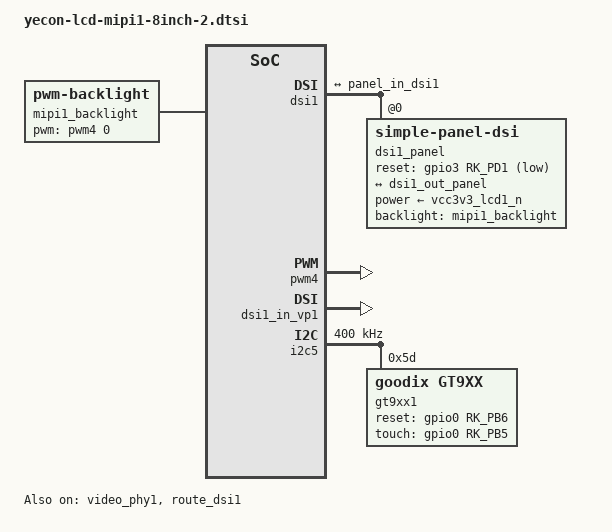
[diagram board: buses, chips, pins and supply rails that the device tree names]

/ {
	mipi1_backlight: mipi1-backlight {
		compatible = "pwm-backlight";
		pwms = <&pwm4 0 25000 0>;
		brightness-levels = <
            0   20  20  21  21  22  22  23
            23  24  24  25  25  26  26  27
            27  28  28  29  29  30  30  31
            31  32  32  33  33  34  34  35
            35  36  36  37  37  38  38  39
            40  41  42  43  44  45  46  47
            48  49  50  51  52  53  54  55
            56  57  58  59  60  61  62  63
            64  65  66  67  68  69  70  71
            72  73  74  75  76  77  78  79
            80  81  82  83  84  85  86  87
            88  89  90  91  92  93  94  95
            96  97  98  99  100 101 102 103
			104 105 106 107 108 109 110 111
			112 113 114 115 116 117 118 119
			120 121 122 123 124 125 126 127
			128 129 130 131 132 133 134 135
			136 137 138 139 140 141 142 143
			144 145 146 147 148 149 150 151
			152 153 154 155 156 157 158 159
			160 161 162 163 164 165 166 167
			168 169 170 171 172 173 174 175
			176 177 178 179 180 181 182 183
			184 185 186 187 188 189 190 191
			192 193 194 195 196 197 198 199
			200 201 202 203 204 205 206 207
			208 209 210 211 212 213 214 215
			216 217 218 219 220 221 222 223
			224 225 226 227 228 229 230 231
			232 233 234 235 236 237 238 239
			240 241 242 243 244 245 246 247
			248 249 250 251 252 253 254 255
		>;
		default-brightness-level = <200>;
	};
};

&vcc3v3_lcd1_n {
    status = "okay";
    gpio = <&gpio0 RK_PC7 GPIO_ACTIVE_HIGH>;
};

&dsi1 {
	status = "okay";
	rockchip,lane-rate = <480>;

	dsi1_panel: panel@0 {
		status = "okay";
		compatible = "simple-panel-dsi";
		reg = <0>;
		backlight = <&mipi1_backlight>;
		prepare-delay-ms = <10>;
		reset-delay-ms = <100>;
		init-delay-ms = <100>;
		enable-delay-ms = <10>;
		disable-delay-ms = <10>;
		unprepare-delay-ms = <10>;

		width-mm = <68>;
		height-mm = <121>;

		dsi,flags = <(MIPI_DSI_MODE_VIDEO | MIPI_DSI_MODE_VIDEO_BURST |
			      MIPI_DSI_MODE_LPM | MIPI_DSI_MODE_EOT_PACKET)>;
		dsi,format = <MIPI_DSI_FMT_RGB888>;
		dsi,lanes = <4>;

		panel-init-sequence = [
			39 00 04 FF 98 81 03
			15 00 02 01 00
			15 00 02 02 00
			15 00 02 03 73
			15 00 02 04 D7
			15 00 02 05 00
			15 00 02 06 08
			15 00 02 07 11
			15 00 02 08 00
			15 00 02 09 3F
			15 00 02 0a 00
			15 00 02 0b 00
			15 00 02 0c 00
			15 00 02 0d 00
			15 00 02 0e 00
			15 00 02 0f 3F
			15 00 02 10 3F
			15 00 02 11 00
			15 00 02 12 00
			15 00 02 13 00
			15 00 02 14 00
			15 00 02 15 00
			15 00 02 16 00
			15 00 02 17 00
			15 00 02 18 00
			15 00 02 19 00
			15 00 02 1a 00
			15 00 02 1b 00
			15 00 02 1c 00
			15 00 02 1d 00
			15 00 02 1e 40
			15 00 02 1f 80
			15 00 02 20 06
			15 00 02 21 01
			15 00 02 22 00
			15 00 02 23 00
			15 00 02 24 00
			15 00 02 25 00
			15 00 02 26 00
			15 00 02 27 00
			15 00 02 28 33
			15 00 02 29 33
			15 00 02 2a 00
			15 00 02 2b 00
			15 00 02 2c 00
			15 00 02 2d 00
			15 00 02 2e 00
			15 00 02 2f 00
			15 00 02 30 00
			15 00 02 31 00
			15 00 02 32 00
			15 00 02 33 00
			15 00 02 34 00
			15 00 02 35 00
			15 00 02 36 00
			15 00 02 37 00
			15 00 02 38 00
			15 00 02 15 00
			15 00 02 3a 00
			15 00 02 3b 00
			15 00 02 3c 00
			15 00 02 3d 00
			15 00 02 3e 00
			15 00 02 3f 00
			15 00 02 40 00
			15 00 02 41 00
			15 00 02 42 00
			15 00 02 43 00
			15 00 02 44 00
			15 00 02 50 01
			15 00 02 51 23
			15 00 02 52 44
			15 00 02 53 67
			15 00 02 54 89
			15 00 02 55 ab
			15 00 02 56 01
			15 00 02 57 23
			15 00 02 58 45
			15 00 02 59 67
			15 00 02 5a 89
			15 00 02 5b ab
			15 00 02 5c cd
			15 00 02 5d ef
			15 00 02 5e 00
			15 00 02 5f 0C
			15 00 02 60 0C
			15 00 02 61 0F
			15 00 02 62 0F
			15 00 02 63 0E
			15 00 02 64 0E
			15 00 02 65 06
			15 00 02 66 07
			15 00 02 67 0D
			15 00 02 68 02
			15 00 02 69 02
			15 00 02 6a 02
			15 00 02 6b 02
			15 00 02 6c 02
			15 00 02 6d 02
			15 00 02 6e 0D
			15 00 02 6f 02
			15 00 02 70 02
			15 00 02 71 05
			15 00 02 72 01
			15 00 02 73 08
			15 00 02 74 00
			15 00 02 75 0C
			15 00 02 76 0C
			15 00 02 77 0F
			15 00 02 78 0F
			15 00 02 79 0E
			15 00 02 7a 0E
			15 00 02 7b 06
			15 00 02 7c 07
			15 00 02 7d 0D
			15 00 02 7e 02
			15 00 02 7f 02
			15 00 02 80 02
			15 00 02 81 02
			15 00 02 82 02
			15 00 02 83 02
			15 00 02 84 0D
			15 00 02 85 02
			15 00 02 86 02
			15 00 02 87 05
			15 00 02 88 01
			15 00 02 89 08
			15 00 02 8A 00
			39 00 04 FF 98 81 04
			15 00 02 6E 3B
			15 00 02 6F 57
			15 00 02 3A 24
			15 00 02 8D 1F
			15 00 02 87 BA
			15 00 02 B2 D1
			15 00 02 88 0B
			15 00 02 38 01
			15 00 02 15 00
			15 00 02 B5 07
			15 00 02 31 75
			15 00 02 3B 98
			39 00 04 FF 98 81 01
			15 00 02 22 0A
			15 00 02 31 09
			15 00 02 53 7B
			15 00 02 55 40
			15 00 02 50 86
			15 00 02 51 82
			15 00 02 60 01
			15 00 02 62 20
			15 00 02 A0 00
			15 00 02 A1 12
			15 00 02 A2 20
			15 00 02 A3 13
			15 00 02 A4 14
			15 00 02 A5 27
			15 00 02 A6 1D
			15 00 02 A7 1F
			15 00 02 A8 7C
			15 00 02 A9 1D
			15 00 02 AA 2A
			15 00 02 AB 6B
			15 00 02 AC 1A
			15 00 02 AD 18
			15 00 02 AE 4E
			15 00 02 AF 24
			15 00 02 B0 2A
			15 00 02 B1 4D
			15 00 02 B2 5B
			15 00 02 B3 23
			15 00 02 C0 00
			15 00 02 C1 13
			15 00 02 C2 20
			15 00 02 C3 12
			15 00 02 C4 15
			15 00 02 C5 28
			15 00 02 C6 1C
			15 00 02 C7 1E
			15 00 02 C8 7B
			15 00 02 C9 1E
			15 00 02 CA 29
			15 00 02 CB 6C
			15 00 02 CC 1A
			15 00 02 CD 19
			15 00 02 CE 4D
			15 00 02 CF 22
			15 00 02 D0 2A
			15 00 02 D1 4D
			15 00 02 D2 5B
			15 00 02 D3 23
			39 00 04 FF 98 81 00
			05 96 01 11
			05 05 01 29
        ];

		disp_timings1: display-timings {
			native-mode = <&dsi1_timing0>;
			dsi1_timing0: timing0 {
				clock-frequency = <72000000>;
				hactive = <800>;
				vactive = <1280>;
				hback-porch = <20>;
				hfront-porch = <20>;
				vback-porch = <6>;
				vfront-porch = <31>;
				hsync-len = <20>;
				vsync-len = <3>;
				hsync-active = <0>;
				vsync-active = <0>;
				de-active = <0>;
				pixelclk-active = <0>;
			};
		};

		ports {
			#address-cells = <1>;
			#size-cells = <0>;

			port@0 {
				reg = <0>;
				panel_in_dsi1: endpoint {
					remote-endpoint = <&dsi1_out_panel>;
				};
			};
		};
	};

	ports {
		#address-cells = <1>;
		#size-cells = <0>;

		port@1 {
			reg = <1>;
			dsi1_out_panel: endpoint {
				remote-endpoint = <&panel_in_dsi1>;
			};
		};
	};
};

&pwm4 {
	status = "okay";
    pinctrl-names = "active";
	/*pinctrl-0 = <&pwm11m0_pins>;*/
};


&video_phy1 {
	status = "okay";
};

&dsi1_panel {
	power-supply = <&vcc3v3_lcd1_n>;
	reset-gpios = <&gpio3 RK_PD1 GPIO_ACTIVE_LOW>;
	pinctrl-names = "default";
	pinctrl-0 = <&lcd1_rst_gpio>;
};

&dsi1_in_vp0 {
	status = "disabled";
};

&dsi1_in_vp1 {
	status = "okay";
};

&route_dsi1 {
	status = "okay";
	connect = <&vp1_out_dsi1>;
};

&pinctrl {
	lcd1 {
		lcd1_rst_gpio: lcd1-rst-gpio {
			rockchip,pins = <3 RK_PA4 RK_FUNC_GPIO &pcfg_pull_none>;
        };
    };

	touch {
		touch_gpio: touch-gpio {
			rockchip,pins =
				<0 RK_PB5 RK_FUNC_GPIO &pcfg_pull_up>,
				<0 RK_PB6 RK_FUNC_GPIO &pcfg_pull_none>;
		};
	};
};

&i2c5 {
	status = "okay";
    clock-frequency = <400000>;

    gt9xx1: gt9xx1@5d {
		status = "okay";
		compatible = "goodix,gt9xx";
		reg = <0x5d>;
		reset-gpio = <&gpio0 RK_PB6 GPIO_ACTIVE_HIGH>;
		touch-gpio = <&gpio0 RK_PB5 IRQ_TYPE_LEVEL_LOW>;
		max-x = <800>;
		max-y = <1280>;
        tp-size = <0>;
		pinctrl-names = "default";
		pinctrl-0 = <&touch_gpio>;
	};
};
